# STM32MP13xx register map
File version: 1.5
CPU: CA7 r0p0, little endian, MPU, FPU, 4 interrupt priority bits
Registers are 32-bit, read-write, reset 0x0 unless marked. A register's access mark holds for its fields unless they carry their own. Offsets are from the block's base; [hi:lo] are bit positions; {n}, {i} and the like mark numbered series; 'fields as' and 'values as' point back to an identical list.

## RCC (part 2 of 7)
Base 0x50000000
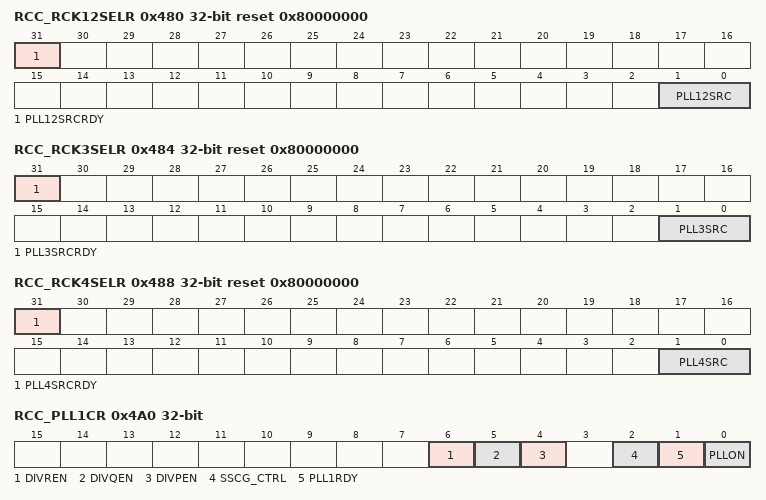
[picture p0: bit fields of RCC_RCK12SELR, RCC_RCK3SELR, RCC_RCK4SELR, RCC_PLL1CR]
0x480 RCC_RCK12SELR access per field reset 0x80000000 — RCC PLL1 and PLL2 reference clock selection register
  [31] PLL12SRCRDY ro — PLL12 source clock switch status Set and reset by hardware to indicate if the PLL12 clock switch transition has been properly performed.
    0=The PLL12 switch is not ready or in position '1x': no clock is generated on its output; 1=The PLL12 switch is ready: the clock switch is selecting the clock given by PLL12SRC[1:0] field. (default after reset)
  [1:0] PLL12SRC rw — Source clock selection for PLL12 Written by software to select the PLL12 source clock. In order to save power when PLL12 is not used, PLL12SRC[1:0] must be set to '1x'. others: No clock send to DIVM1 divider and PLL12
    0=HSI selected as PLL12 clock (hsi_ck) (default after reset); 1=HSE selected as PLL12 clock (hse_ck)
0x484 RCC_RCK3SELR access per field reset 0x80000000 — RCC PLL3 reference clock selection register
  [31] PLL3SRCRDY ro — PLL3 source clock switch status Set and reset by hardware to indicate if the PLL3 clock switch transition has been properly performed.
    0=The PLL3 switch is not ready or in position '11': no clock is generated on its output; 1=The PLL3 switch is ready: the clock switch is selecting the clock given by PLL3SRC[1:0] field. (default after reset)
  [1:0] PLL3SRC rw — Source clock selection for PLL3 Written by software to select the PLL3 clock source. In order to save power, when PLL3 is not used, PLL3SRC[1:0] must be set to '11'.
    0=HSI selected as PLL clock (hsi_ck) (default after reset); 1=HSE selected as PLL clock (hse_ck); 2=CSI selected as PLL clock (csi_ck); 3=No clock send to DIVM3 divider and PLL3
0x488 RCC_RCK4SELR access per field reset 0x80000000 — RCC PLL4 reference clock selection register
  [31] PLL4SRCRDY ro — PLL4 source clock switch status Set and reset by hardware to indicate if the PLL4 clock switch transition has been properly performed.
    0=The PLL4 switch is not ready or in position '11': no clock is generated on its output; 1=The PLL4 switch is ready: the clock switch is selecting the clock given by PLL4SRC[1:0] field. (default after reset)
  [1:0] PLL4SRC rw — Source clock selection for PLL4 Written by software to select the PLL4 clock source.
    0=HSI selected as PLL clock (hsi_ck) (default after reset); 1=HSE selected as PLL clock (hse_ck); 2=CSI selected as PLL clock (csi_ck); 3=Signal I2S_CKIN used as source clock
0x4A0 RCC_PLL1CR access per field — RCC PLL1 control register
  [6] DIVREN rw — PLL1 DIVR divider output enable Set and reset by software to enable the pll1_r_ck output of the PLL1. In order to save power, when the pll1_r_ck is not needed, DIVREN and DIVR must be set to '0'.
    0=pll1_r_ck output is disabled (default after reset); 1=pll1_r_ck output is enabled
  [5] DIVQEN rw — PLL1 DIVQ divider output enable Set and reset by software to enable the pll1_q_ck output of the PLL1. In order to save power, when the pll1_q_ck is not needed, DIVQEN and DIVQ must be set to '0'.
    0=pll1_q_ck output is disabled (default after reset); 1=pll1_q_ck output is enabled
  [4] DIVPEN rw — PLL1 DIVP divider output enable Set and reset by software to enable the pll1_p_ck output of the PLL1. In order to save power, when the pll1_p_ck is not needed, DIVPEN and DIVP must be set to '0'.
    0=pll1_p_ck output is disabled (default after reset); 1=pll1_p_ck output is enabled
  [2] SSCG_CTRL rw — Spread Spectrum Clock Generator of PLL1 enable Set and reset by software to enable the spread spectrum clock generator of PLL1, in order to reduce the amount of EMI peaks.
    0=Clock Spreading Generator disabled (default after reset); 1=Clock Spreading Generator enabled
  [1] PLL1RDY ro — PLL1 clock ready flag Set by hardware to indicate that the PLL1 is locked.
    0=PLL1 unlocked (default after reset); 1=PLL1 locked
  [0] PLLON rw — PLL1 enable.
    0=PLL1 OFF (default after reset); 1=PLL1 is ON, and ref1_ck is provided to the PLL1
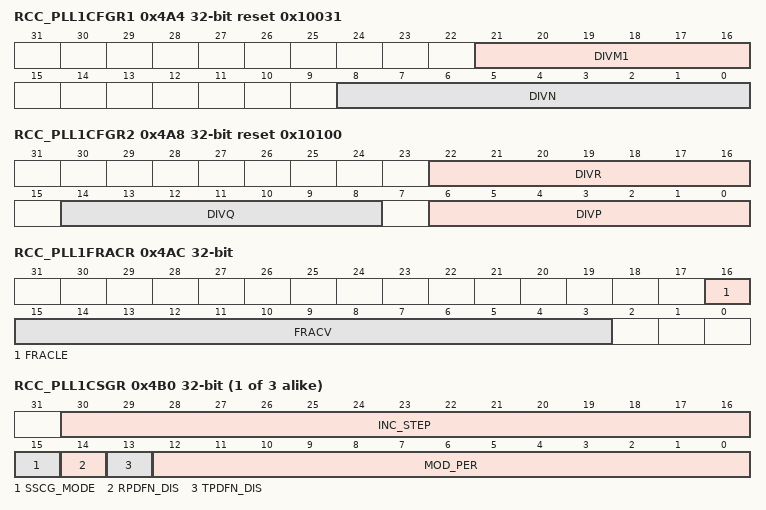
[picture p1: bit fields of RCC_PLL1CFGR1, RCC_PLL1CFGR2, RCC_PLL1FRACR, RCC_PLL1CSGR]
0x4A4 RCC_PLL1CFGR1 reset 0x10031 — RCC PLL1 configuration register 1
  [21:16] DIVM1 — Prescaler for PLL1 Set and cleared by software to configure the prescaler of the PLL1. ...
    0=bypass; 1=division by 2 (default after reset); 2=division by 3; 63=division by 64
  [8:0] DIVN — Multiplication factor for PLL1 VCO Written by software to control the multiplication factor of the VCO. Warning: the software has to set correctly these bits to ensure that the VCO output frequency is between its valid frequency range, which is: 992 to 1800 MHz. VCO output frequency = Fref1_ck x 2 x (DIVN+1), when value 0 has been loaded into FRACV, with: - Valid division ratios for DIVN: between 25 and 100 - The input frequency Fref1_ck between 8 and 16 MHz ... ... Others: wrong configurations
    24=Division ratio is 25; 25=Division ratio is 26; 49=Division ratio is 50 (default after reset); 99=Division ratio is 100
0x4A8 RCC_PLL1CFGR2 reset 0x10100 — RCC PLL1 configuration register 2
  [22:16] DIVR — PLL1 DIVR division factor Written by software to control the frequency of the pll1_r_ck clock. ...
    0=pll1_r_ck = fout1_ck; 1=pll1_r_ck = fout1_ck / 2 (default after reset); 2=pll1_r_ck = fout1_ck / 3; 127=pll1_r_ck = fout1_ck / 128
  [14:8] DIVQ — PLL1 DIVQ division factor Written by software to control the frequency of the pll1_q_ck clock. ...
    0=pll1_q_ck = fout1_ck; 1=pll1_q_ck = fout1_ck / 2 (default after reset); 2=pll1_q_ck = fout1_ck / 3; 127=pll1_q_ck = fout1_ck / 128
  [6:0] DIVP — PLL1 DIVP division factor Written by software to control the frequency of the pll1_p_ck clock. Odd division factors are not recommended due to duty cycle degradation. ...
    0=pll1_p_ck = fout1_ck (default after reset); 1=pll1_p_ck = fout1_ck / 2; 2=pll1_p_ck = fout1_ck / 3; 127=pll1_p_ck = fout1_ck / 128
0x4AC RCC_PLL1FRACR — RCC PLL1 fractional register
  [16] FRACLE — PLL1 fractional latch enable Set and reset by software to latch the content of FRACV into the Sigma-Delta modulator. In order to latch the FRACV value into the Sigma-Delta modulator, FRACLE must be set to '0', then set to '1': the transition 0 to '1' transfers the content of FRACV into the modulator. Refer to and for additional information on the PLL programming.
  [15:3] FRACV — Fractional part of the multiplication factor for PLL1 VCO Written by software to control the fractional part of the multiplication factor of the VCO. These bits can be written at any time, allowing dynamic fine-tuning of the PLL1 VCO. Warning: the software has to set correctly these bits to ensure that the VCO output frequency is between its valid frequency range, which is: 800 to 1600 MHz VCO output frequency = Fref1_ck x ((DIVN+1) + (FRACV / 8192)), with - DIVN shall be between 4 and 512 - FRACV can be between 0 and 8191 - The input frequency Fref1_ck shall be between 4 and 16 MHz In order to change the FRACV value on-the-fly even if the PLL is enabled, the application has to proceed as follow: - set the bit FRACLE to '0', - write the new fractional value into FRACV, - set the bit FRACLE to '1'.
{0x480+0x30*i} RCC_PLL{i}CSGR (i=1..3) — RCC PLL{i} clock spreading generator register
  [30:16] INC_STEP — Modulation Depth Adjustment for PLL{i} Written by software to adjust the modulation depth of the clock spreading generator.
  [15] SSCG_MODE — Spread spectrum clock generator mode Set and reset by software to select the clock spreading mode.
    0=Center-spread modulation selected (default after reset); 1=Down-spread modulation selected
  [14] RPDFN_DIS — Dithering RPDF noise control Set and reset by software. This bit is used to enable or disable the injection of a dithering noise into the SSCG modulator. This dithering noise is generated using a rectangular probability density function.
    0=Dithering noise injection enabled (default after reset); 1=Dithering noise injection disabled
  [13] TPDFN_DIS — Dithering TPDF noise control Set and reset by software. This bit is used to enable or disable the injection of a dithering noise into the SSCG modulator. This dithering noise is generated using a triangular probability density function.
    values as RPDFN_DIS
  [12:0] MOD_PER — Modulation Period Adjustment for PLL{i} Written by software to adjust the modulation period of the clock spreading generator.
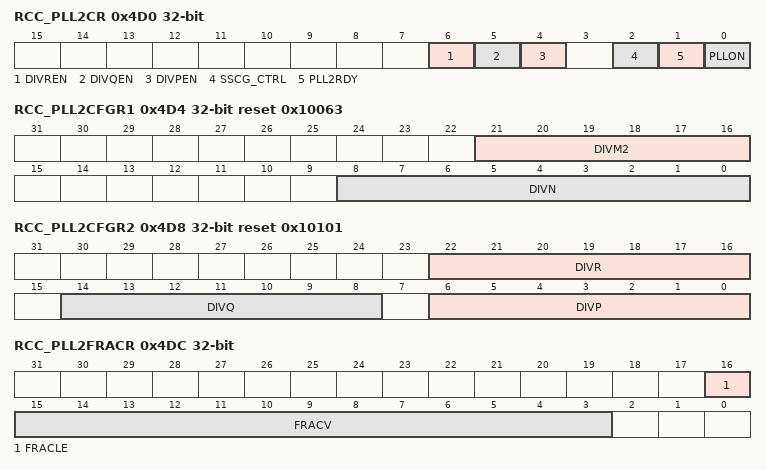
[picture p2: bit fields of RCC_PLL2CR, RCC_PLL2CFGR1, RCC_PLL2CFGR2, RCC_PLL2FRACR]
0x4D0 RCC_PLL2CR access per field — RCC PLL2 control register
  [6] DIVREN rw — PLL2 DIVR divider output enable Set and reset by software to enable the pll2_r_ck output of the PLL2. In order to save power, when the pll2_r_ck is not needed, DIVREN and DIVR must be set to '0'.
    0=pll2_r_ck output is disabled (default after reset); 1=pll2_r_ck output is enabled
  [5] DIVQEN rw — PLL2 DIVQ divider output enable Set and reset by software to enable the pll2_q_ck output of the PLL2. In order to save power, when the pll2_q_ck is not needed, DIVQEN and DIVQ must be set to '0'.
    0=pll2_q_ck output is disabled (default after reset); 1=pll2_q_ck output is enabled
  [4] DIVPEN rw — PLL2 DIVP divider output enable Set and reset by software to enable the pll2_p_ck output of the PLL2. In order to save power, when the pll2_p_ck is not needed, DIVPEN and DIVP must be set to '0'.
    0=pll2_p_ck output is disabled (default after reset); 1=pll2_p_ck output is enabled
  [2] SSCG_CTRL rw — Clock Spreading Generator of PLL2 enable Set and reset by software to enable the clock spreading generator of PLL2, in order to reduce the amount of EMI peaks.
    values as RCC_PLL1CR.SSCG_CTRL
  [1] PLL2RDY ro — PLL2 clock ready flag Set by hardware to indicate that the PLL2 is locked.
    0=PLL2 unlocked (default after reset); 1=PLL2 locked
  [0] PLLON rw — PLL2 enable Set and cleared by software to enable the PLL2.
    0=PLL2 OFF (default after reset); 1=PLL2 ON, and ref2_ck is provided to the PLL2
0x4D4 RCC_PLL2CFGR1 reset 0x10063 — RCC PLL2 configuration register 1
  [21:16] DIVM2 — Prescaler for PLL2 Set and cleared by software to configure the prescaler of the PLL2. ...
    values as RCC_PLL1CFGR1.DIVM1
  [8:0] DIVN — Multiplication factor for PLL2 VCO Written by software to control the multiplication factor of the VCO. Warning: the software has to set correctly these bits to ensure that the VCO output frequency is between its valid frequency range, which is: 800 to 1600 MHz. VCO output frequency = Fref2_ck x (DIVN+1), when value 0 has been loaded into FRACV, with: - Valid division ratios for DIVN: between 25 and 100 - The input frequency Fref2_ck between 8 and 16 MHz Others: wrong configurations ... ...
    24=Division ratio is 25; 25=Division ratio is 26; 49=Division ratio is 50; 99=Division ratio is 100 (default after reset)
0x4D8 RCC_PLL2CFGR2 reset 0x10101 — RCC PLL2 configuration register 2
  [22:16] DIVR — PLL2 DIVR division factor Written by software to control the frequency of the pll2_r_ck clock. ...
    0=pll2_r_ck = fout2_ck; 1=pll2_r_ck = fout2_ck / 2 (default after reset); 2=pll2_r_ck = fout2_ck / 3; 127=pll2_r_ck = fout2_ck / 128
  [14:8] DIVQ — PLL2 DIVQ division factor Written by software to control the frequency of the pll2_q_ck clock. ...
    0=pll2_q_ck = fout2_ck; 1=pll2_q_ck = fout2_ck / 2 (default after reset); 2=pll2_q_ck = fout2_ck / 3; 127=pll2_q_ck = fout2_ck / 128
  [6:0] DIVP — PLL2 DIVP division factor Written by software to control the frequency of the pll2_p_ck clock. ...
    0=pll2_p_ck = fout2_ck; 1=pll2_p_ck = fout2_ck / 2 (default after reset); 2=pll2_p_ck = fout2_ck / 3; 127=pll2_p_ck = fout2_ck / 128
0x4DC RCC_PLL2FRACR — RCC PLL2 fractional register
  [16] FRACLE — PLL2 fractional latch enable Set and reset by software to latch the content of FRACV into the Sigma-Delta modulator. In order to latch the FRACV value into the Sigma-Delta modulator, FRACLE must be set to '0', then set to '1': the transition 0 to '1' transfers the content of FRACV into the modulator. Refer to and for additional information on the PLL programming.
  [15:3] FRACV — Fractional part of the multiplication factor for PLL2 VCO Written by software to control the fractional part of the multiplication factor of the VCO. These bits can be written at any time, allowing dynamic fine-tuning of the PLL2 VCO. Warning: the software has to set correctly these bits to ensure that the VCO output frequency is between its valid frequency range, which is: 800 to 1600 MHz VCO output frequency = Fref2_ck x ((DIVN+1) + (FRACV / 8192)), with - DIVN shall be between 4 and 512 - FRACV can be between 0 and 8191 - The input frequency Fref2_ck shall be between 4 and 16 MHz In order to change the FRACV value on-the-fly even if the PLL is enabled, the application has to proceed as follow: - set the bit FRACLE to '0', - write the new fractional value into FRACV, - set the bit FRACLE to '1'.
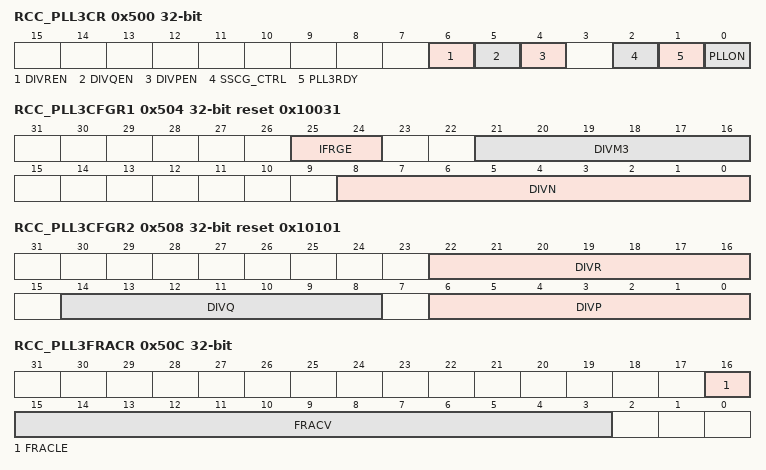
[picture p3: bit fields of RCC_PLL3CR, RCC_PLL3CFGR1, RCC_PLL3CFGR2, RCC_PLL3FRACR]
0x500 RCC_PLL3CR access per field — RCC PLL3 control register
  [6] DIVREN rw — PLL3 DIVR divider output enable Set and reset by software to enable the pll3_r_ck output of the PLL3. Cleared by hardware when entering a Stop mode or Standby. In order to save power, when the pll3_r_ck is not needed, DIVREN and DIVR must be set to '0'.
    0=pll3_r_ck output is disabled (default after reset); 1=pll3_r_ck output is enabled
  [5] DIVQEN rw — PLL3 DIVQ divider output enable Set and reset by software to enable the pll3_q_ck output of the PLL3. Cleared by hardware when entering a Stop mode or Standby. In order to save power, when the pll3_q_ck is not needed, DIVQEN and DIVQ must be set to '0'.
    0=pll3_q_ck output is disabled (default after reset); 1=pll3_q_ck output is enabled
  [4] DIVPEN rw — PLL3 DIVP divider output enable Set and reset by software to enable the pll3_p_ck output of the PLL3. Cleared by hardware when entering a Stop mode or Standby. In order to save power, when the pll3_p_ck is not needed, DIVPEN and DIVP must be set to '0'.
    0=pll3_p_ck output is disabled (default after reset); 1=pll3_p_ck output is enabled
  [2] SSCG_CTRL rw — Clock Spreading Generator of PLL3 enable Set and reset by software to enable the clock spreading generator of PLL3, in order to reduce the amount of EMI peaks.
    values as RCC_PLL1CR.SSCG_CTRL
  [1] PLL3RDY ro — PLL3 clock ready flag Set by hardware to indicate that the PLL3 is locked.
    0=PLL3 unlocked (default after reset); 1=PLL3 locked
  [0] PLLON rw — PLL3 enable
    0=PLL3 OFF (default after reset); 1=PLL3 ON, and ref3_ck is provided to the PLL3
0x504 RCC_PLL3CFGR1 reset 0x10031 — RCC PLL3 configuration register 1
  [25:24] IFRGE — PLL3 input frequency range Written by software to select the proper reference frequency range used for PLL3. x0: The PLL3 input (ref3_ck) clock range frequency is between 4 and 8 MHz (default after reset) x1: The PLL3 input (ref3_ck) clock range frequency is between 8 and 16 MHz. Note that if ref3_ck is equal to 8Â MHz, it is recommended to set IFRGE = 'x1â
  [21:16] DIVM3 — Prescaler for PLL3 Set and cleared by software to configure the prescaler of the PLL3. ...
    values as RCC_PLL1CFGR1.DIVM1
  [8:0] DIVN — Multiplication factor for PLL3 VCO Written by software to control the multiplication factor of the VCO. Warning: the software has to set correctly these bits to ensure that the VCO output frequency is between its valid frequency range, which is between 400 and 800 MHz. VCO output frequency = Fref3_ck x (DIVN+1), when value 0 has been loaded into FRACV, with: - Valid division ratios for DIVN: between 25 and 200 - The input frequency Fref3_ck between 4 and 16 MHz ... ... Others: wrong configurations
    24=Division ratio is 25; 25=Division ratio is 26; 26=Division ratio is 27; 49=Division ratio is 50 (default after reset); 199=Division ratio is 200
0x508 RCC_PLL3CFGR2 reset 0x10101 — RCC PLL3 configuration register 2
  [22:16] DIVR — PLL3 DIVR division factor Written by software to control the frequency of the pll3_r_ck clock. ...
    0=pll3_r_ck = vco3_ck; 1=pll3_r_ck = vco3_ck / 2 (default after reset); 2=pll3_r_ck = vco3_ck / 3; 127=pll3_r_ck = vco3_ck / 128
  [14:8] DIVQ — PLL3 DIVQ division factor Written by software to control the frequency of the pll3_q_ck clock. ...
    0=pll3_q_ck = vco3_ck; 1=pll3_q_ck = vco3_ck / 2 (default after reset); 2=pll3_q_ck = vco3_ck / 3; 127=pll3_q_ck = vco3_ck / 128
  [6:0] DIVP — PLL3 DIVP division factor Written by software to control the frequency of the pll3_p_ck clock. ...
    0=pll3_p_ck = vco3_ck; 1=pll3_p_ck = vco3_ck / 2 (default after reset); 2=pll3_p_ck = vco3_ck / 3; 127=pll3_p_ck = vco3_ck / 128
0x50C RCC_PLL3FRACR — RCC PLL3 Fractional register
  [16] FRACLE — PLL3 fractional latch enable Set and reset by software to latch the content of FRACV into the Sigma-Delta modulator. In order to latch the FRACV value into the Sigma-Delta modulator, FRACLE must be set to '0', then set to '1': the transition 0 to '1' transfers the content of FRACV into the modulator. Refer to and for additional information on the PLL programming.
  [15:3] FRACV — Fractional part of the multiplication factor for PLL3 VCO Written by software to control the fractional part of the multiplication factor of the VCO. These bits can be written at any time, allowing dynamic fine-tuning of the PLL3 VCO. Warning: the software has to set correctly these bits to ensure that the VCO output frequency is between its valid frequency range, which is between 400 and 800 MHz. VCO output frequency = Fref3_ck x ((DIVN+1) + (FRACV / 8192)), with - DIVN shall be between 4 and 512 - FRACV can be between 0 and 8191 - The input frequency Fref3_ck shall be between 1 and 16 MHz In order to change the FRACV value on-the-fly even if the PLL is enabled, the application has to proceed as follow: - set the bit FRACLE to '0', - write the new fractional value into FRACV, - set the bit FRACLE to '1'.
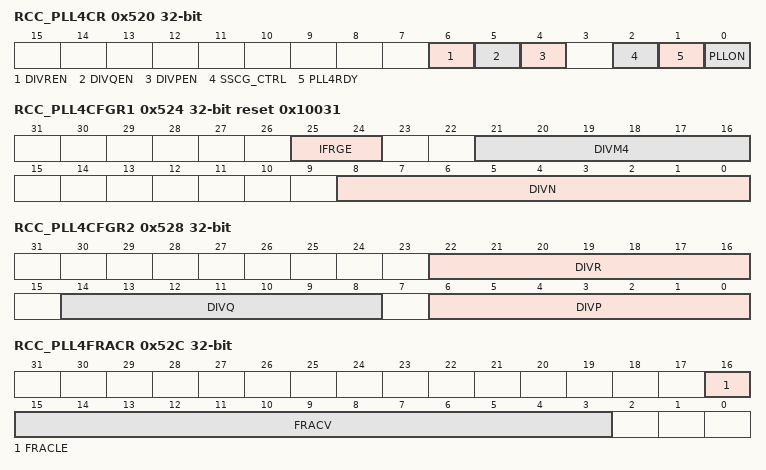
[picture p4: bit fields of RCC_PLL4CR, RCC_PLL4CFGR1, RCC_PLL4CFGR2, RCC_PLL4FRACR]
0x520 RCC_PLL4CR access per field — RCC PLL4 control register
  [6] DIVREN rw — PLL4 DIVR divider output enable Set and reset by software to enable the pll4_r_ck output of the PLL4. Cleared by hardware when entering a Stop mode or Standby. In order to save power, when the pll4_r_ck is not needed, DIVREN must be set to '0'.
    0=pll4_r_ck output is disabled (default after reset); 1=pll4_r_ck output is enabled
  [5] DIVQEN rw — PLL4 DIVQ divider output enable Set and reset by software to enable the pll4_q_ck output of the PLL4. Cleared by hardware when entering a Stop mode or Standby. In order to save power, when the pll4_q_ck is not needed, DIVQEN must be set to '0'.
    0=pll4_q_ck output is disabled (default after reset); 1=pll4_q_ck output is enabled
  [4] DIVPEN rw — PLL4 DIVP divider output enable Set and reset by software to enable the pll4_p_ck output of the PLL4. Cleared by hardware when entering a Stop mode or Standby. In order to save power, when the pll4_p_ck is not needed, DIVPEN must be set to '0'.
    0=pll4_p_ck output is disabled (default after reset); 1=pll4_p_ck output is enabled
  [2] SSCG_CTRL rw — Clock Spreading Generator of PLL4 enable Set and reset by software to enable the clock spreading generator of PLL4, in order to reduce the amount of EMI peaks.
    values as RCC_PLL1CR.SSCG_CTRL
  [1] PLL4RDY ro — PLL4 clock ready flag Set by hardware to indicate that the PLL4 is locked.
    0=PLL4 unlocked (default after reset); 1=PLL4 locked
  [0] PLLON rw — PLL4 enable
    0=PLL4 OFF (default after reset); 1=PLL4 ON, and ref4_ck is provided to the PLL4
0x524 RCC_PLL4CFGR1 reset 0x10031 — RCC PLL4 configuration register 1
  [25:24] IFRGE — PLL4 input frequency range Written by software to select the proper reference frequency range used for PLL4. x0: The PLL4 input (ref4_ck) clock range frequency is between 4 and 8 MHz (default after reset) x1: The PLL4 input (ref4_ck) clock range frequency is between 8 and 16 MHz Note that if ref3_ck is equal to 8Â MHz, it is recommended to set IFRGE = 'x1â
  [21:16] DIVM4 — Prescaler for PLL4 Set and cleared by software to configure the prescaler of the PLL4. ...
    values as RCC_PLL1CFGR1.DIVM1
  [8:0] DIVN — Multiplication factor for PLL4 VCO Written by software to control the multiplication factor of the VCO. Warning: the software has to set correctly these bits to ensure that the VCO output frequency is between its valid frequency range, which is between 400 and 800 MHz. VCO output frequency = Fref4_ck x (DIVN+1), when value 0 has been loaded into FRACV, with: - Valid division ratios for DIVN: between 25 and 200 - The input frequency Fref4_ck between 4 and 16 MHz ... ... Others: wrong configurations
    values as RCC_PLL3CFGR1.DIVN
0x528 RCC_PLL4CFGR2 — RCC PLL4 configuration register 2
  [22:16] DIVR — PLL4 DIVR division factor Written by software to control the frequency of the pll4_r_ck clock. ...
    0=pll4_r_ck = vco4_ck (default after reset); 1=pll4_r_ck = vco4_ck / 2; 2=pll4_r_ck = vco4_ck / 3; 127=pll4_r_ck = vco4_ck / 128
  [14:8] DIVQ — PLL4 DIVQ division factor Written by software to control the frequency of the pll4_q_ck clock. ...
    0=pll4_q_ck = vco4_ck (default after reset); 1=pll4_q_ck = vco4_ck / 2; 2=pll4_q_ck = vco4_ck / 3; 127=pll4_q_ck = vco4_ck / 128
  [6:0] DIVP — PLL4 DIVP division factor Written by software to control the frequency of the pll4_p_ck clock. ...
    0=pll4_p_ck = vco4_ck (default after reset); 1=pll4_p_ck = vco4_ck / 2; 2=pll4_p_ck = vco4_ck / 3; 127=pll4_p_ck = vco4_ck / 128
0x52C RCC_PLL4FRACR — RCC PLL4 fractional register
  [16] FRACLE — PLL4 fractional latch enable Set and reset by software to latch the content of FRACV into the Sigma-Delta modulator. In order to latch the FRACV value into the Sigma-Delta modulator, FRACLE must be set to '0', then set to '1': the transition 0 to '1' transfers the content of FRACV into the modulator. Refer to Section: Refer to and dividers for additional information.
  [15:3] FRACV — Fractional part of the multiplication factor for PLL4 VCO Written by software to control the fractional part of the multiplication factor of the VCO. These bits can be written at any time, allowing dynamic fine-tuning of the PLL4 VCO. Warning: the software has to set correctly these bits to ensure that the VCO output frequency is between its valid frequency range, which is between 400 and 800 MHz. VCO output frequency = Fref4_ck x ((DIVN+1) + (FRACV / 8192)), with - DIVN shall be between 4 and 512 - FRACV can be between 0 and 8191 - The input frequency Fref4_ck shall be between 1 and 16 MHz In order to change the FRACV value on-the-fly even if the PLL is enabled, the application has to proceed as follow: - set the bit FRACLE to '0', - write the new fractional value into FRACV, - set the bit FRACLE to '1'.
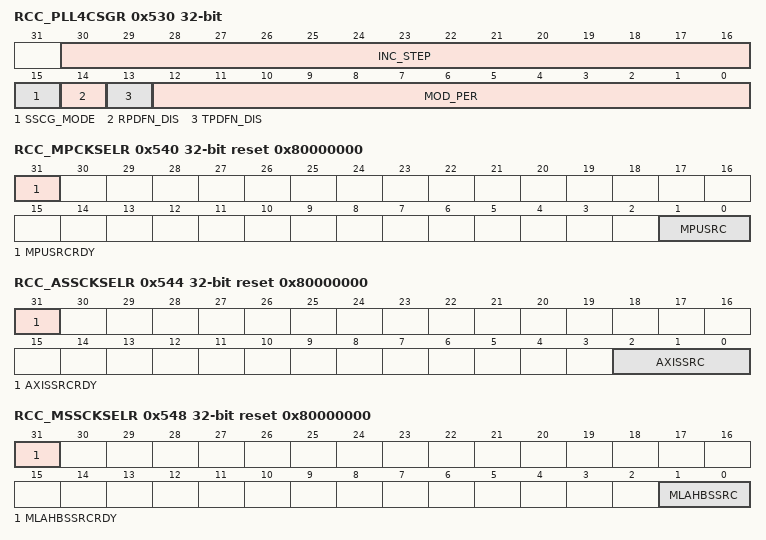
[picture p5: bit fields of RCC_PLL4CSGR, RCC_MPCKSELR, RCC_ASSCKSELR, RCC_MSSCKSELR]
0x530 RCC_PLL4CSGR — RCC PLL4 clock spreading generator register
  [30:16] INC_STEP — Modulation Depth Adjustment for PLL4 Written by software to adjust the modulation depth of the clock spreading generator.
  [15] SSCG_MODE — Spread spectrum clock generator mode Set and reset by software to select the clock spreading mode.
    values as RCC_PLL1CSGR.SSCG_MODE
  [14] RPDFN_DIS — Dithering RPDF noise control Set and reset by software. This bit is used to enable or disable the injection of a dithering noise into the SSCG modulator. This dithering noise is generated using a rectangular probability density function.
    values as RCC_PLL1CSGR.RPDFN_DIS
  [13] TPDFN_DIS — Dithering TPDF noise control Set and reset by software. This bit is used to enable or disable the injection of a dithering noise into the SSCG modulator. This dithering noise is generated using a triangular probability density function.
    values as RCC_PLL1CSGR.RPDFN_DIS
  [12:0] MOD_PER — Modulation Period Adjustment for PLL4 Written by software to adjust the modulation period of the clock spreading generator.
0x540 RCC_MPCKSELR access per field reset 0x80000000 — RCC MPU clock selection register
  [31] MPUSRCRDY ro — MPU clock switch status Set and reset by hardware to indicate if the MPU clock switch transition has been properly performed.
    0=The MPU switch is not ready: no clock is generated on its output; 1=The MPU switch is ready: the clock switch is selecting the clock given by MPUSRC field. (default after reset)
  [1:0] MPUSRC rw — MPU clock switch Written by software to select the MPU sub-system clock source (mpuss_ck). Note that MPUDIV is disabled if MPUSRC[1:0] is different from '11'. Be sure that MPUDIV is different from '000' before setting MPUSRC to '11'.
    0=HSI selected as MPU sub-system clock (hsi_ck) (default after reset); 1=HSE selected as MPU sub-system clock (hse_ck); 2=PLL1 selected as MPU sub-system clock (pll1_p_ck); 3=divided PLL1 pll1_p_ck clock is selected as MPU sub-system clock, c.f. RCC_MPCKDIVR.MPUDIV[3:0]
0x544 RCC_ASSCKSELR access per field reset 0x80000000 — RCC AXI sub-system clock selection register.
  [31] AXISSRCRDY ro — AXI sub-system clock switch status Set and reset by hardware to indicate if the AXI clock switch transition has been properly performed.
    0=The AXI sub-system switch is not ready or in positions higher than '011': no clock is generated on its output; 1=The AXI sub-system switch is ready: the clock switch is selecting the clock given by AXISSRC field. (default after reset)
  [2:0] AXISSRC rw — AXI sub-system clock switch Written by software to select the AXI sub-system clock source (axiss_ck). others: axiss_ck is gated
    0=HSI selected as AXI sub-system clock (hsi_ck) (default after reset); 1=HSE selected as AXI sub-system clock (hse_ck); 2=PLL2 selected as AXI sub-system clock (pll2_p_ck)
0x548 RCC_MSSCKSELR access per field reset 0x80000000 — RCC MLAHB sub-system clock selection register
  [31] MLAHBSSRCRDY ro — MLAHB sub-system clock switch status Set and reset by hardware to indicate if the MLAHB clock switch transition has been properly performed.
    0=The MLAHB sub-system switch is not ready or in positions higher than '011': no clock is generated on its output; 1=The MLAHB sub-system switch is ready: the clock switch is selecting the clock given by MLAHBSSRC field. (default after reset)
  [1:0] MLAHBSSRC rw — MLAHB sub-system clock switch Written by software to select the MLAHB sub-system clock source (mlahbss_ck). Reset by hardware in order to select hsi_ck when the system exits from one of the Stop modes.
    0=HSI selected as MLAHB sub-system clock (hsi_ck) (default after reset); 1=HSE selected as MLAHB sub-system clock (hse_ck); 2=CSI selected as MLAHB sub-system clock (csi_ck); 3=PLL3 selected as MLAHB sub-system clock (pll3_p_ck)
0x54C RCC_CPERCKSELR — RCC common peripheral kernel clock selection register
  [1:0] CKPERSRC — Oscillator selection for kernel clock Set and cleared by software.
    0=hsi_ker_ck clock selected (default after reset); 1=csi_ker_ck clock selected; 2=hse_ker_ck clock selected; 3=Clock disabled
0x560 RCC_RTCDIVR — RCC RTC clock division register
  [5:0] RTCDIV — HSE division factor for RTC clock Set and cleared by software to divide the HSE to generate a clock for RTC. Caution: The software has to set these bits correctly to ensure that the clock supplied to the RTC is lower than 4 MHz. These bits must be configured if needed before selecting the RTC clock source. Note that when the RTCSRC is different from 3, this divider is disabled (does not provide clock). ...
    0=HSE (default after reset); 1=HSE/2; 2=HSE/3; 3=HSE/4; 62=HSE/63; 63=HSE/64
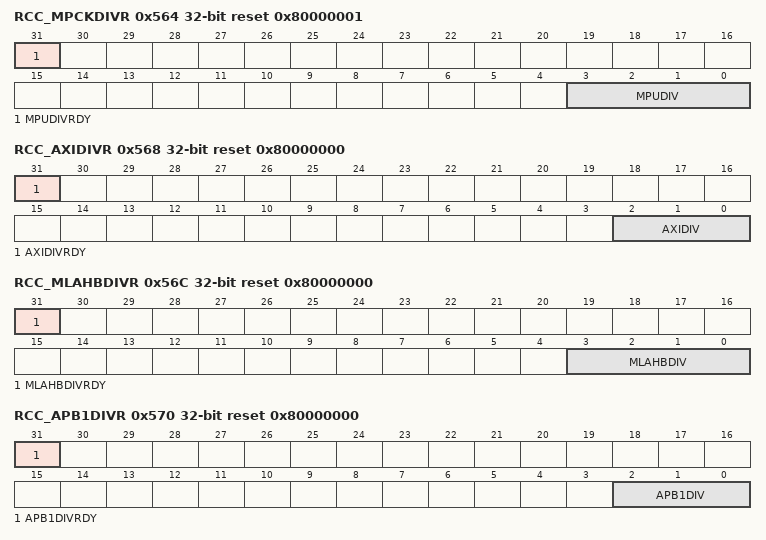
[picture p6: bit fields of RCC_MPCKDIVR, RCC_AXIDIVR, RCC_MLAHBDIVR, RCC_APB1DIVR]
0x564 RCC_MPCKDIVR access per field reset 0x80000001 — RCC MPU clock divider register
  [31] MPUDIVRDY ro — MPU sub-system clock divider status Set and reset by hardware to indicate if the new division factor is taken into account. This bit significant only when MPUSRC[1:0] = '11'.
    0=The new division factor is not yet taken into account; 1=The new division factor is taken into account. (default after reset)
  [3:0] MPUDIV rw — MPU Core clock divider Written by software to control the MPU clock division factor when the MPUSRC is set to position 3. It is possible to change this division ratio on-the-fly. It impacts only the frequency of the MPU clock. The clocks are divided with the new prescaler factor, from 1 to 16 pll1_p_ck cycles after MPUDIV update. The application can check if the new division factor is taken into account by reading back the MPUDIVRDY flag. Note that this divider is disabled if MPUSRC[1:0] is different from '11'. 0x<n>: The mpuss_ck is equal to pll1_p_ck divided by 0x<n>+1
    0=The MPUDIV is disabled; i.e. no clock generated; 1=The mpuss_ck is equal to pll1_p_ck divided by 2 (default after reset); 2=The mpuss_ck is equal to pll1_p_ck divided by 3; 15=The mpuss_ck is equal to pll1_p_ck divided by 16
0x568 RCC_AXIDIVR access per field reset 0x80000000 — RCC AXI clock divider register
  [31] AXIDIVRDY ro — AXI sub-system clock divider status Set and reset by hardware to indicate if the new division factor is taken into account.
    values as RCC_MPCKDIVR.MPUDIVRDY
  [2:0] AXIDIV rw — AXI, AHB5 and AHB6 clock divider Written by software to control the AXI, AHB5 and AHB6 clock division factor. It is possible to change this division ratio on-the-fly. It impacts the frequency of AXI, APB4, APB5 AHB5 and AHB6 clocks. The clocks are divided with the new prescaler factor, from 1 to 4 axiss_ck cycles after AXIDIV update. The application can check if the new division factor is taken into account by reading back the AXIDIVRDY flag. others: axiss_ck / 4
    0=axiss_ck (default after reset); 1=axiss_ck / 2; 2=axiss_ck / 3
0x56C RCC_MLAHBDIVR access per field reset 0x80000000 — RCC MLAHB clock divider register
  [31] MLAHBDIVRDY ro — MLAHB clock prescaler status Set and reset by hardware to indicate if the new division factor is taken into account.
    values as RCC_MPCKDIVR.MPUDIVRDY
  [3:0] MLAHBDIV rw — MLAHB clock divider Written by software to control the MLAHB clock division factor. Changing this division ratio has an impact on the frequency of MLAHB clock, and all bus matrix clocks. The clocks are divided with the new prescaler factor, from 1 to 512 cycles of mlahbss_ck, after MLAHBDIV update. The application can check if the new division factor is taken into account by reading back the MLAHBDIVRDY flag. others: mlahbss_ck divided by 512
    0=mlahbss_ck not divided (default after reset); 1=mlahbss_ck divided by 2; 2=mlahbss_ck divided by 4; 3=mlahbss_ck divided by 8; 4=mlahbss_ck divided by 16; 5=mlahbss_ck divided by 32; 6=mlahbss_ck divided by 64; 7=mlahbss_ck divided by 128; 8=mlahbss_ck divided by 256
0x570 RCC_APB1DIVR access per field reset 0x80000000 — RCC APB1 clock divider register
  [31] APB1DIVRDY ro — APB1 clock prescaler status Set and reset by hardware to indicate if the new division factor is taken into account.
    values as RCC_MPCKDIVR.MPUDIVRDY
  [2:0] APB1DIV rw — APB1 clock divider Written by software to control the APB1 clock division factor. The APB1 peripheral clock is divided with the new prescaler factor, from 1 to 16 mlhclk cycles after APB1DIV update. The application can check if the new division factor is taken into account by reading back the APB1DIVRDY flag. others: Not allowed
    0=mlhclk (default after reset); 1=mlhclk / 2; 2=mlhclk / 4; 3=mlhclk / 8; 4=mlhclk / 16
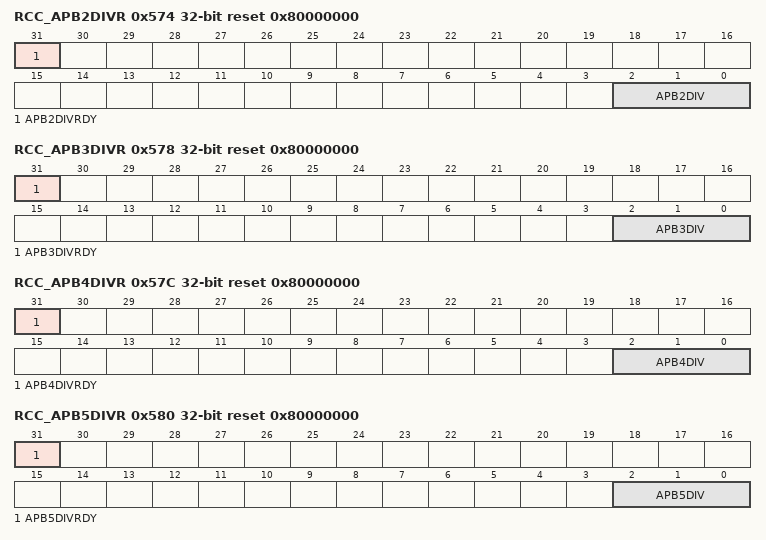
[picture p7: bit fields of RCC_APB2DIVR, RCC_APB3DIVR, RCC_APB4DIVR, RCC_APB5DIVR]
0x574 RCC_APB2DIVR access per field reset 0x80000000 — RCC APB2 clock divider register
  [31] APB2DIVRDY ro — APB2 clock prescaler status Set and reset by hardware to indicate if the new division factor is taken into account.
    values as RCC_MPCKDIVR.MPUDIVRDY
  [2:0] APB2DIV rw — APB2 clock divider Written by software to control the APB2 clock division factor. The APB2 clock is divided with the new prescaler factor, from 1 to 16 mlhclk cycles after APB2DIV update. The application can check if the new division factor is taken into account by reading back the APB2DIVRDY flag. others: Not allowed
    values as RCC_APB1DIVR.APB1DIV
0x578 RCC_APB3DIVR access per field reset 0x80000000 — RCC APB3 clock divider register
  [31] APB3DIVRDY ro — APB3 clock prescaler status Set and reset by hardware to indicate if the new division factor is taken into account.
    values as RCC_MPCKDIVR.MPUDIVRDY
  [2:0] APB3DIV rw — APB3 clock divider Written by software to control the APB3 clock division factor. The APB3 clock is divided by this new prescaler factor, from 1 to 16 hclk cycles after APB3DIV update. The application can check if the new division factor is taken into account by reading back the APB3DIVRDY flag. others: hclk / 16
    0=hclk (default after reset); 1=hclk / 2; 2=hclk / 4; 3=hclk / 8
0x57C RCC_APB4DIVR access per field reset 0x80000000 — RCC APB4 clock divider register.
  [31] APB4DIVRDY ro — APB4 clock divider status Set and reset by hardware to indicate if the new division factor is taken into account.
    values as RCC_MPCKDIVR.MPUDIVRDY
  [2:0] APB4DIV rw — APB4 clock divider Written by software to control the APB4 clock division factor. It is possible to change this division ratio on-the-fly. It impacts only the frequency of APB4 clock. The clocks are divided with the new prescaler factor, from 1 to 16 aclk cycles after APB4DIV update. The application can check if the new division factor is taken into account by reading back the APB4DIVRDY flag. others: aclk / 16
    0=aclk (default after reset); 1=aclk / 2; 2=aclk / 4; 3=aclk / 8
0x580 RCC_APB5DIVR access per field reset 0x80000000 — RCC APB5 clock divider register
  [31] APB5DIVRDY ro — APB5 clock divider status Set and reset by hardware to indicate if the new division factor is taken into account.
    values as RCC_MPCKDIVR.MPUDIVRDY
  [2:0] APB5DIV rw — APB5 clock divider Written by software to control the APB5 clock division factor. It is possible to change this division ratio on-the-fly. It impacts only the frequency of APB5 clock. The clocks are divided with the new prescaler factor, from 1 to 16 aclk cycles after APB5DIV update. The application can check if the new division factor is taken into account by reading the APB5DIVRDY flag. others: aclk / 16
    values as RCC_APB4DIVR.APB4DIV
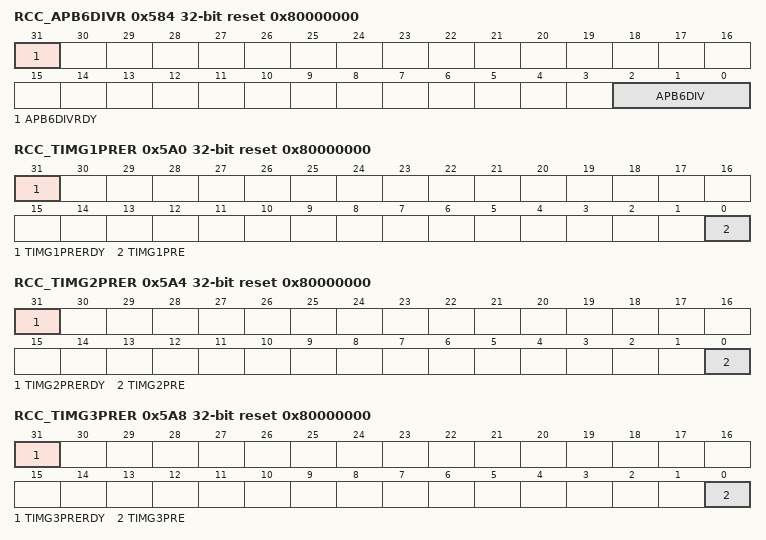
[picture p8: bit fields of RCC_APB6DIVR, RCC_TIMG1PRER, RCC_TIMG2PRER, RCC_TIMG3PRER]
0x584 RCC_APB6DIVR access per field reset 0x80000000 — RCC APB6 clock divider register
  [31] APB6DIVRDY ro — APB6 clock divider status Set and reset by hardware to indicate if the new division factor is taken into account.
    values as RCC_MPCKDIVR.MPUDIVRDY
  [2:0] APB6DIV rw — APB6 clock divider Written by software to control the APB6 clock division factor. It is possible to change this division ratio on-the-fly. It impacts only the frequency of APB6 clock. The clocks are divided with the new prescaler factor, from 1 to 16 aclk cycles after APB6DIV update. The application can check if the new division factor is taken into account by reading the APB6DIVRDY flag. others: aclk / 16
    values as RCC_APB4DIVR.APB4DIV
0x5A0 RCC_TIMG1PRER access per field reset 0x80000000 — RCC APB1 timers group1 prescaler register.
  [31] TIMG1PRERDY ro — Timers clocks prescaler status Set and reset by hardware to indicate if the new division factor is taken into account.
    0=The new division factor is not yet taken into account; 1=The new division factor is taken into account (default after reset)
  [0] TIMG1PRE rw — Timers clocks prescaler selection This bit is set and reset by software to control the clock frequency of all the timers connected to APB1 domain. Refer to .
    0=The Timers kernel clock is equal to mlhclk if APB1DIV is corresponding to a division by 1 or 2, else it is equal to 2 x Fpclk1 (default after reset); 1=The Timers kernel clock is equal to mlhclk if APB1DIV is corresponding to division by 1, 2 or 4, else it is equal to 4 x Fpclk1
0x5A4 RCC_TIMG2PRER access per field reset 0x80000000 — RCC APB2 timers group2 prescaler register
  [31] TIMG2PRERDY ro — Timers clocks prescaler status Set and reset by hardware to indicate if the new division factor is taken into account.
    values as RCC_TIMG1PRER.TIMG1PRERDY
  [0] TIMG2PRE rw — Timers clocks prescaler selection This bit is set and reset by software to control the clock frequency of all the timers connected to APB2 domain. Refer to .
    0=The Timers kernel clock is equal to mlhclk if APB2DIV is corresponding to a division by 1 or 2, else it is equal to 2 x Fpclk2 (default after reset); 1=The Timers kernel clock is equal to mlhclk if APB2DIV is corresponding to division by 1, 2 or 4, else it is equal to 4 x Fpclk2
0x5A8 RCC_TIMG3PRER access per field reset 0x80000000 — RCC APB6 timers group3 prescaler register
  [31] TIMG3PRERDY ro — Timers clocks prescaler status Set and reset by hardware to indicate if the new division factor is taken into account.
    values as RCC_TIMG1PRER.TIMG1PRERDY
  [0] TIMG3PRE rw — Timers clocks prescaler selection This bit is set and reset by software to control the clock frequency of all the timers connected to APB6 domain. Refer to .
    0=The Timers kernel clock is equal to mlhclk if APB6DIV is corresponding to a division by 1 or 2, else it is equal to 2 x Fpclk6 (default after reset); 1=The Timers kernel clock is equal to mlhclk if APB6DIV is corresponding to division by 1, 2 or 4, else it is equal to 4 x Fpclk6
